# nrf9120_mlm1_modem register map
Vendor: Nordic Semiconductor; Series: nrf91; File version: 1
CPU: CM4 r0p1, little endian, MPU, no FPU, 3 interrupt priority bits
Registers are 32-bit, read-write, reset 0x0 unless marked. A register's access mark holds for its fields unless they carry their own. Offsets are from the block's base; [hi:lo] are bit positions; lines under a group give offsets from that group; {n}, {i} and the like mark numbered series; 'fields as' and 'values as' point back to an identical list.

## IPC — Inter Processor Communication
Base 0x4002B000
{0x0+4i} TASKS_SEND[{i}] (i=0..6) wo — Description collection: Trigger events on channel enabled in SEND_CNF[n].
  [0] TASKS_SEND — Trigger events on channel enabled in SEND_CNF[n].
    1=Trigger task
{0x100+4i} EVENTS_RECEIVE[{i}] (i=0..4) — Description collection: Event received on one or more of the enabled channels in RECEIVE_CNF[n].
  [0] EVENTS_RECEIVE — Event received on one or more of the enabled channels in RECEIVE_CNF[n].
    0=NotGenerated (Event not generated); 1=Generated (Event generated)
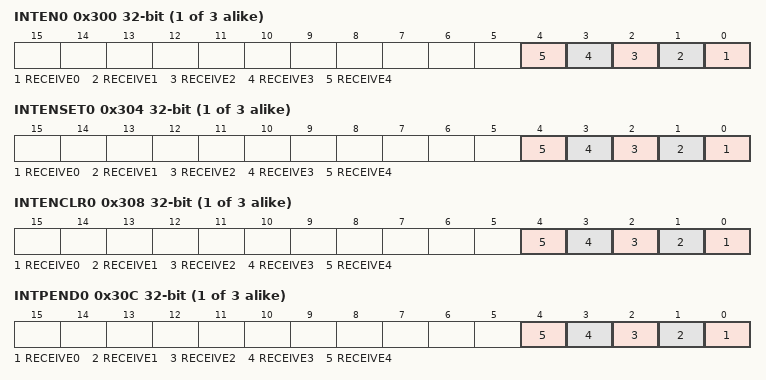
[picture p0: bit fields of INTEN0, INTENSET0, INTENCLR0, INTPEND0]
{0x300+0x10*i} INTEN{i} (i=0..2) — Enable or disable interrupt
  [all] fields
    0=Disabled; 1=Enabled
  [n] RECEIVE{n} (n=0..4) — Enable or disable interrupt for event RECEIVE[{n}]
{0x304+0x10*i} INTENSET{i} (i=0..2) — Enable interrupt
  [all] fields
    on read: 0=Disabled (Read: Disabled); 1=Enabled (Read: Enabled) | on write: 1=Set (Enable)
  [n] RECEIVE{n} (n=0..4) — Write '1' to enable interrupt for event RECEIVE[{n}]
{0x308+0x10*i} INTENCLR{i} (i=0..2) — Disable interrupt
  [all] fields
    on read: 0=Disabled (Read: Disabled); 1=Enabled (Read: Enabled) | on write: 1=Clear (Disable)
  [n] RECEIVE{n} (n=0..4) — Write '1' to disable interrupt for event RECEIVE[{n}]
{0x30C+0x10*i} INTPEND{i} ro (i=0..2) — Pending interrupts
  [all] fields
    on read: 0=NotPending (Read: Not pending); 1=Pending (Read: Pending)
  [n] RECEIVE{n} (n=0..4) — Read pending status of interrupt for event RECEIVE[{n}]
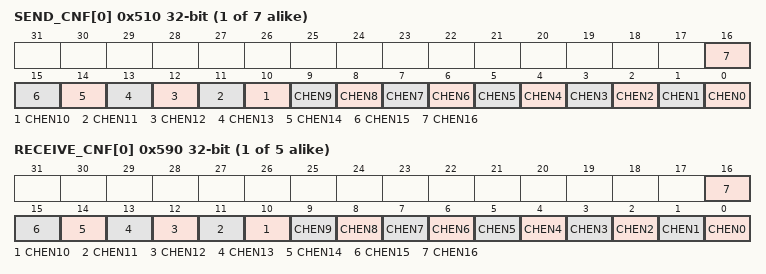
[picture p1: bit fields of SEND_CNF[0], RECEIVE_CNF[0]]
{0x510+4i} SEND_CNF[{i}] (i=0..6) — Description collection: Send event configuration for TASKS_SEND[n].
  [all] fields
    0=Disable broadcast; 1=Enable broadcast
  [n] CHEN{n} (n=0..16) — Enable broadcasting on channel {n}.
{0x590+4i} RECEIVE_CNF[{i}] (i=0..4) — Description collection: Receive event configuration for EVENTS_RECEIVE[n].
  [all] fields
    0=Disable events; 1=Enable events
  [n] CHEN{n} (n=0..16) — Enable subscription to channel {n}.
{0x610+4i} GPMEM[{i}] (i=0..1) — Description collection: General purpose memory.
  [31:0] GPMEM — General purpose memory

## M2M0 — Memory to Memory DMA 0
Base 0x4002E000
Same registers: M2M1 0x4002F000
0x00 TASKS_START wo — Start DMA transfer
  [0] TASKS_START
    1=Trigger task
0x04 TASKS_STOP wo — Stop DMA transfer
  [0] TASKS_STOP
    1=Trigger task
0x100 EVENTS_END — DMA transfer complete
  [0] EVENTS_END
    0=NotGenerated (Event not generated); 1=Generated (Event generated)
0x104 EVENTS_STARTED — DMA transfer started
  [0] EVENTS_STARTED
    values as EVENTS_END.EVENTS_END
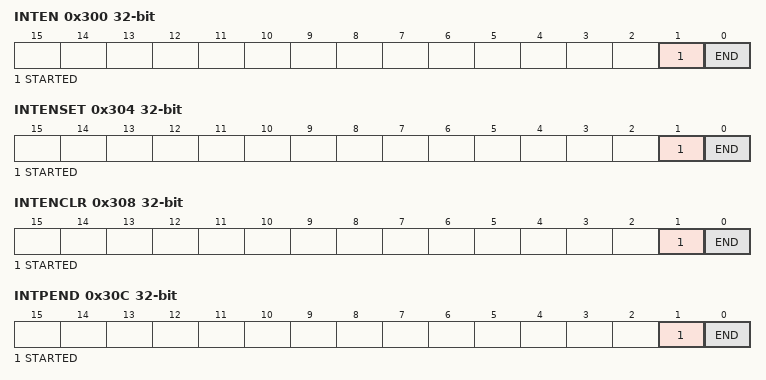
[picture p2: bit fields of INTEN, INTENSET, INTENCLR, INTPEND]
0x300 INTEN — Enable or disable interrupt
  [1] STARTED — Enable or disable interrupt for event STARTED
    0=Disabled; 1=Enabled
  [0] END — Enable or disable interrupt for event END
    0=Disabled; 1=Enabled
0x304 INTENSET — Enable interrupt
  [1] STARTED — Write '1' to enable interrupt for event STARTED
    on read: 0=Disabled (Read: Disabled); 1=Enabled (Read: Enabled) | on write: 1=Set (Enable)
  [0] END — Write '1' to enable interrupt for event END
    values as STARTED
0x308 INTENCLR — Disable interrupt
  [1] STARTED — Write '1' to disable interrupt for event STARTED
    on read: 0=Disabled (Read: Disabled); 1=Enabled (Read: Enabled) | on write: 1=Clear (Disable)
  [0] END — Write '1' to disable interrupt for event END
    values as STARTED
0x30C INTPEND ro — Pending interrupts
  [1] STARTED — Read pending status of interrupt for event STARTED
    on read: 0=NotPending (Read: Not pending); 1=Pending (Read: Pending)
  [0] END — Read pending status of interrupt for event END
    values as STARTED
0x510 IN group — Memory to memory input channel
  0x00 PTR — Data pointer
  0x04 MAXCNT — Maximum number of bytes in input and output buffer
    [7:0] MAXCNT
  0x08 AMOUNT ro — Number of bytes transferred in the last transaction
    [7:0] AMOUNT
  0x0C LIST — EasyDMA list type
    [2:0] LIST — List type
      0=Disabled (Disable EasyDMA list); 1=ArrayList (Use array list)
0x520 OUT group — Memory to memory output channel
  0x00 PTR — Data pointer
  0x04 AMOUNT ro — Number of bytes transferred in the last transaction
    [7:0] AMOUNT
  0x08 LIST — EasyDMA list type
    fields as IN.LIST
